# earlgrey register map
Vendor: lowRISC; File version: 0.1
CPU: ibex rev01, little endian, no MPU, no FPU, VTOR, 2 interrupt priority bits, 2 interrupts
Registers are 32-bit, read-write, no defined reset value unless marked. A register's access mark holds for its fields unless they carry their own. Offsets are from the block's base; [hi:lo] are bit positions; {n}, {i} and the like mark numbered series.

## KMAC — Accelerator for Keccak-based keyed hash message authentication code and SHA-3 hash functions; with SCA and FI countermeasures
Base 0x41120000
0x40 CFG_REGWEN ro — Controls the configurability of !!CFG_SHADOWED register.This register ensures the contents of !!CFG_SHADOWED register cannot bechanged by the software while the KMAC/SHA3 is in operation mode.
  [0] en — Configuration enable.
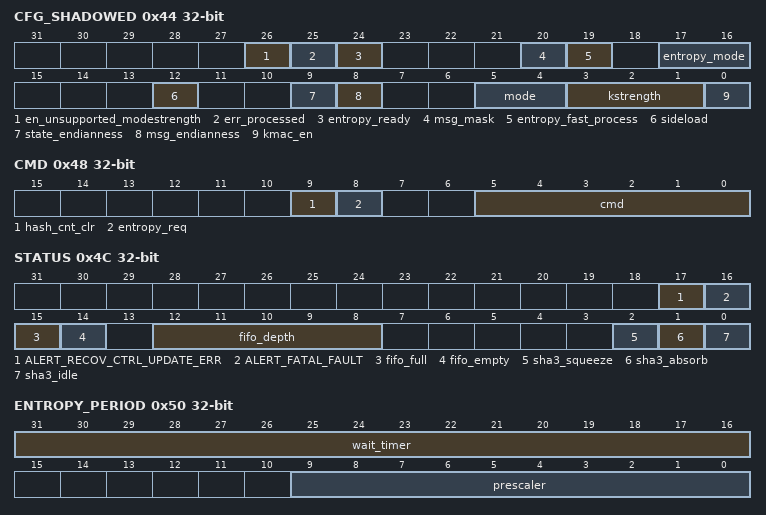
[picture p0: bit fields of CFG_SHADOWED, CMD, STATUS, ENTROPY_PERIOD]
0x44 CFG_SHADOWED — KMAC Configuration register.This register is updated when the hashing engine is in Idle.If the software updates the register while the engine computes, theupdated value will be discarded.
  [26] en_unsupported_modestrength — Enable Unsupported Mode and Strength configs.SW may set this field for KMAC to move forward with unsupportedKeccak Mode and Strength configurations, such as cSHAKE512.If not set, KMAC won't propagate the SW command (CmdStart) to therest of the blocks (AppIntf, KMAC Core, SHA3).
  [25] err_processed — When error occurs and one of the state machine stays at Error handling state, SW may process the error based on ERR_CODE, then let FSM back to the reset state
  [24] entropy_ready — Entropy Ready status.Software sets this field to allow the entropy generator in KMAC tofetch the entropy and run.
  [20] msg_mask — Message Masking with PRNG.If 1, KMAC applies PRNG to the input messages to the Keccak modulewhen KMAC mode is on.
  [19] entropy_fast_process — Entropy Fast process mode.If 1, entropy logic uses garbage data while not processing the KMACkey block. It will re-use previous entropy value and will notexpand the entropy when it is consumed. Only it refreshes theentropy while processing the secret key block. This process shouldnot be used if SCA resistance is required because it may cause sidechannel leakage.
  [17:16] entropy_mode — Entropy ModeUsing this field, software can configure mode of operation of the internal pseudo-random number generator (PRNG).For the hardware to actually switch to an entropy mode other than the default idle_mode, software further needs to set the !!CFG_SHADOWED.entropy_ready bit.After that point, the hardware cannot be made to return to idle_mode unless the module is reset.
  [12] sideload — Sideloaded Key.If 1, KMAC uses KeyMgr sideloaded key for SW initiated KMACoperation. KMAC uses the sideloaded key regardless of thisconfiguration when KeyMgr initiates the KMAC operation forKey Derivation Function (KDF).
  [9] state_endianness — State Endianness.If 1 then each individual word in the !!STATE output registeris converted to big-endian byte order.The order of the words in relation to one another is notchanged.This setting does not affect how the state is interpretedduring computation.
  [8] msg_endianness — Message Endianness.If 1 then each individual multi-byte value, regardless of itsalignment, written to !!MSG_FIFO will be added to the messagein big-endian byte order.If 0, each value will be added to the message in little-endianbyte order.A message written to !!MSG_FIFO one byte at a time will not beaffected by this setting.From a hardware perspective byte swaps are performed on a TL-ULword granularity.
  [5:4] mode — Keccak hashing mode.This module supports SHA3 main hashing algorithm and the partof its derived functions, SHAKE and cSHAKE with limitations.This field is to select the mode.
  [3:1] kstrength — Hashing Strength3 bit field to select the security strength of SHA3 hashingengine. If mode field is set to SHAKE or cSHAKE, only 128 and256 strength can be selected. Other value will result errorwhen hashing starts.
  [0] kmac_en — KMAC datapath enable.If this bit is 1, the incoming message is processed in KMACwith the secret key.
0x48 CMD — KMAC/ SHA3 command register.This register is to control the KMAC to start accepting message,to process the message, and to manually run additional keccakrounds at the end. Only at certain stage, the CMD affects to thecontrol logic. It follows the sequence of`start` --> `process` --> {`run` if needed --> } `done`
  [9] hash_cnt_clr — If writes 1, it clears the hash (KMAC) counter in the entropy module
  [8] entropy_req — SW triggered Entropy RequestIf writes 1 to this field
  [5:0] cmd — Issue a command to the KMAC/SHA3 IP. The command is sparseencoded. To prevent sw from writing multiple commands at once,the field is defined as enum.
0x4C STATUS ro — KMAC/SHA3 Status register.
  [17] ALERT_RECOV_CTRL_UPDATE_ERR — An update error has not occurred (0) or has occured (1) in the shadowed Control Register.KMAC operation needs to be restarted by re-writing the Control Register.
  [16] ALERT_FATAL_FAULT — No fatal fault has occurred inside the KMAC unit (0).A fatal fault has occured and the KMAC unit needs to be reset (1),Examples for such faults includei) TL-UL bus integrity faultii) storage errors in the shadow registersiii) errors in the message, round, or key counteriv) any internal FSM entering an invalid statev) an error in the redundant lfsr
  [15] fifo_full — Message FIFO Full indicator
  [14] fifo_empty — Message FIFO Empty indicator.The FIFO's `Pass` parameter is set to `1'b 1`. So, by default, ifthe SHA engine is ready, the write data to FIFO just passesthrough.In this case, `fifo_depth` remains **0**. `fifo_empty`, however,lowers the value to **0** for a cycle, then goes back to the emptystate, **1**.See the "Message FIFO" section in the spec for the reason.
  [12:8] fifo_depth — Count of occupied entries in the message FIFO.
  [2] sha3_squeeze — If 1, SHA3 completes sponge absorbing stage.In this stage, SW can manually run the hashing engine.
  [1] sha3_absorb — If 1, SHA3 is receiving message stream and processing it
  [0] sha3_idle — If 1, SHA3 hashing engine is in idle state.
0x50 ENTROPY_PERIOD — Entropy Timer Periods.
  [31:16] wait_timer — EDN request wait timer.The entropy module in KMAC waits up to this field in the timer pulseafter it sends request to EDN module. If the timer expires, theentropy module moves to an error state and notifies to the system.If there is a pending EDN request during wait timer update, then this update is delayed until the EDN request is complete.If 0, the entropy module waits the EDN response always. If EDN doesnot respond in this configuration, the software shall reset the IP.
  [9:0] prescaler — EDN Wait timer prescaler.EDN Wait timer has 16 bit value. The timer value is increased when the timer pulse is generated. Timer pulse is raises when the number of the clock cycles hit this prescaler value.The exact period of the timer pulse is unknown as the KMAC input clock may contain jitters.
0x54 ENTROPY_REFRESH_HASH_CNT ro — Entropy Refresh CounterKMAC entropy can be refreshed after the given threshold KMAC operationsrun. If the KMAC hash counter !!ENTROPY_REFRESH_HASH_CNT hits (GTE) theconfigured threshold !!ENTROPY_REFRESH_THRESHOLD_SHADOWED, the entropymodule in the KMAC IP requests new seed to EDN and reset the KMAChash counter.If the threshold is 0, the refresh by the counter does not work. And thecounter is only reset by the CMD.hash_cnt_clr CSR bit.
  [9:0] hash_cnt — Hash (KMAC) counter
0x58 ENTROPY_REFRESH_THRESHOLD_SHADOWED — Entropy Refresh ThresholdKMAC entropy can be refreshed after the given threshold KMAC operationsrun. If the KMAC hash counter !!ENTROPY_REFRESH_HASH_CNT hits (GTE) theconfigured threshold !!ENTROPY_REFRESH_THRESHOLD_SHADOWED, the entropymodule in the KMAC IP requests new seed to EDN and reset the KMAChash counter.If the threshold is 0, the refresh by the counter does not work. And thecounter is only reset by the CMD.hash_cnt_clr CSR bit.
  [9:0] threshold — Hash Threshold
{0x5C+4i} ENTROPY_SEED_{i} wo (i=0..4) — Entropy SeedEntropy seed registers for the integrated entropy generator.If !!CFG_SHADOWED.entropy_mode is set to sw_mode, software first needs to set!!CFG_SHADOWED.entropy_ready and then write the !!ENTROPY_SEED_0 -!!ENTROPY_SEED_4 registers in ascending order. Software writes one 32-bit valueto every register which is subsequently loaded into the corresponding 32-bit LFSRchunk of the entropy generator.After writing all !!ENTROPY_SEED_0 registers, the entropy generator will startits operation. After this point, writing these registers has no longer anyeffect.
  [31:0] seed_{i} — 32-bit chunk of the entropy generator seed
0x70 KEY_SHARE0_0 wo — KMAC Secret KeyKMAC secret key can be up to 512 bit.Order of the secret key is:key[512:0] = {KEY15, KEY14, ... , KEY0};The registers are allowed to be updated when the engine is in Idle state.If the engine computes the hash, it discards any attempts to update the secret keysand report an error.Current KMAC supports up to 512 bit secret key. It is the swresponsibility to keep upper bits of the secret key to 0.
  [31:0] key_0 — 32-bit chunk of up-to 512-bit Secret Key
0x74 KEY_SHARE0_1 wo — KMAC Secret KeyKMAC secret key can be up to 512 bit.Order of the secret key is:key[512:0] = {KEY15, KEY14, ... , KEY0};The registers are allowed to be updated when the engine is in Idle state.If the engine computes the hash, it discards any attempts to update the secret keysand report an error.Current KMAC supports up to 512 bit secret key. It is the swresponsibility to keep upper bits of the secret key to 0.
  [31:0] key_1 — 32-bit chunk of up-to 512-bit Secret Key
0x78 KEY_SHARE0_2 wo — KMAC Secret KeyKMAC secret key can be up to 512 bit.Order of the secret key is:key[512:0] = {KEY15, KEY14, ... , KEY0};The registers are allowed to be updated when the engine is in Idle state.If the engine computes the hash, it discards any attempts to update the secret keysand report an error.Current KMAC supports up to 512 bit secret key. It is the swresponsibility to keep upper bits of the secret key to 0.
  [31:0] key_2 — 32-bit chunk of up-to 512-bit Secret Key
0x7C KEY_SHARE0_3 wo — KMAC Secret KeyKMAC secret key can be up to 512 bit.Order of the secret key is:key[512:0] = {KEY15, KEY14, ... , KEY0};The registers are allowed to be updated when the engine is in Idle state.If the engine computes the hash, it discards any attempts to update the secret keysand report an error.Current KMAC supports up to 512 bit secret key. It is the swresponsibility to keep upper bits of the secret key to 0.
  [31:0] key_3 — 32-bit chunk of up-to 512-bit Secret Key
0x80 KEY_SHARE0_4 wo — KMAC Secret KeyKMAC secret key can be up to 512 bit.Order of the secret key is:key[512:0] = {KEY15, KEY14, ... , KEY0};The registers are allowed to be updated when the engine is in Idle state.If the engine computes the hash, it discards any attempts to update the secret keysand report an error.Current KMAC supports up to 512 bit secret key. It is the swresponsibility to keep upper bits of the secret key to 0.
  [31:0] key_4 — 32-bit chunk of up-to 512-bit Secret Key
0x84 KEY_SHARE0_5 wo — KMAC Secret KeyKMAC secret key can be up to 512 bit.Order of the secret key is:key[512:0] = {KEY15, KEY14, ... , KEY0};The registers are allowed to be updated when the engine is in Idle state.If the engine computes the hash, it discards any attempts to update the secret keysand report an error.Current KMAC supports up to 512 bit secret key. It is the swresponsibility to keep upper bits of the secret key to 0.
  [31:0] key_5 — 32-bit chunk of up-to 512-bit Secret Key
0x88 KEY_SHARE0_6 wo — KMAC Secret KeyKMAC secret key can be up to 512 bit.Order of the secret key is:key[512:0] = {KEY15, KEY14, ... , KEY0};The registers are allowed to be updated when the engine is in Idle state.If the engine computes the hash, it discards any attempts to update the secret keysand report an error.Current KMAC supports up to 512 bit secret key. It is the swresponsibility to keep upper bits of the secret key to 0.
  [31:0] key_6 — 32-bit chunk of up-to 512-bit Secret Key
0x8C KEY_SHARE0_7 wo — KMAC Secret KeyKMAC secret key can be up to 512 bit.Order of the secret key is:key[512:0] = {KEY15, KEY14, ... , KEY0};The registers are allowed to be updated when the engine is in Idle state.If the engine computes the hash, it discards any attempts to update the secret keysand report an error.Current KMAC supports up to 512 bit secret key. It is the swresponsibility to keep upper bits of the secret key to 0.
  [31:0] key_7 — 32-bit chunk of up-to 512-bit Secret Key
0x90 KEY_SHARE0_8 wo — KMAC Secret KeyKMAC secret key can be up to 512 bit.Order of the secret key is:key[512:0] = {KEY15, KEY14, ... , KEY0};The registers are allowed to be updated when the engine is in Idle state.If the engine computes the hash, it discards any attempts to update the secret keysand report an error.Current KMAC supports up to 512 bit secret key. It is the swresponsibility to keep upper bits of the secret key to 0.
  [31:0] key_8 — 32-bit chunk of up-to 512-bit Secret Key
0x94 KEY_SHARE0_9 wo — KMAC Secret KeyKMAC secret key can be up to 512 bit.Order of the secret key is:key[512:0] = {KEY15, KEY14, ... , KEY0};The registers are allowed to be updated when the engine is in Idle state.If the engine computes the hash, it discards any attempts to update the secret keysand report an error.Current KMAC supports up to 512 bit secret key. It is the swresponsibility to keep upper bits of the secret key to 0.
  [31:0] key_9 — 32-bit chunk of up-to 512-bit Secret Key
0x98 KEY_SHARE0_10 wo — KMAC Secret KeyKMAC secret key can be up to 512 bit.Order of the secret key is:key[512:0] = {KEY15, KEY14, ... , KEY0};The registers are allowed to be updated when the engine is in Idle state.If the engine computes the hash, it discards any attempts to update the secret keysand report an error.Current KMAC supports up to 512 bit secret key. It is the swresponsibility to keep upper bits of the secret key to 0.
  [31:0] key_10 — 32-bit chunk of up-to 512-bit Secret Key
0x9C KEY_SHARE0_11 wo — KMAC Secret KeyKMAC secret key can be up to 512 bit.Order of the secret key is:key[512:0] = {KEY15, KEY14, ... , KEY0};The registers are allowed to be updated when the engine is in Idle state.If the engine computes the hash, it discards any attempts to update the secret keysand report an error.Current KMAC supports up to 512 bit secret key. It is the swresponsibility to keep upper bits of the secret key to 0.
  [31:0] key_11 — 32-bit chunk of up-to 512-bit Secret Key
0xA0 KEY_SHARE0_12 wo — KMAC Secret KeyKMAC secret key can be up to 512 bit.Order of the secret key is:key[512:0] = {KEY15, KEY14, ... , KEY0};The registers are allowed to be updated when the engine is in Idle state.If the engine computes the hash, it discards any attempts to update the secret keysand report an error.Current KMAC supports up to 512 bit secret key. It is the swresponsibility to keep upper bits of the secret key to 0.
  [31:0] key_12 — 32-bit chunk of up-to 512-bit Secret Key
0xA4 KEY_SHARE0_13 wo — KMAC Secret KeyKMAC secret key can be up to 512 bit.Order of the secret key is:key[512:0] = {KEY15, KEY14, ... , KEY0};The registers are allowed to be updated when the engine is in Idle state.If the engine computes the hash, it discards any attempts to update the secret keysand report an error.Current KMAC supports up to 512 bit secret key. It is the swresponsibility to keep upper bits of the secret key to 0.
  [31:0] key_13 — 32-bit chunk of up-to 512-bit Secret Key
0xA8 KEY_SHARE0_14 wo — KMAC Secret KeyKMAC secret key can be up to 512 bit.Order of the secret key is:key[512:0] = {KEY15, KEY14, ... , KEY0};The registers are allowed to be updated when the engine is in Idle state.If the engine computes the hash, it discards any attempts to update the secret keysand report an error.Current KMAC supports up to 512 bit secret key. It is the swresponsibility to keep upper bits of the secret key to 0.
  [31:0] key_14 — 32-bit chunk of up-to 512-bit Secret Key
0xAC KEY_SHARE0_15 wo — KMAC Secret KeyKMAC secret key can be up to 512 bit.Order of the secret key is:key[512:0] = {KEY15, KEY14, ... , KEY0};The registers are allowed to be updated when the engine is in Idle state.If the engine computes the hash, it discards any attempts to update the secret keysand report an error.Current KMAC supports up to 512 bit secret key. It is the swresponsibility to keep upper bits of the secret key to 0.
  [31:0] key_15 — 32-bit chunk of up-to 512-bit Secret Key
0xB0 KEY_SHARE1_0 wo — KMAC Secret Key, 2nd share.KMAC secret key can be up to 512 bit.Order of the secret key is:key[512:0] = {KEY15, KEY14, ... , KEY0};The registers are allowed to be updated when the engine is in Idle state.If the engine computes the hash, it discards any attempts to update the secret keysand report an error.Current KMAC supports up to 512 bit secret key. It is the swresponsibility to keep upper bits of the secret key to 0.
  [31:0] key_0 — 32-bit chunk of up-to 512-bit Secret Key
0xB4 KEY_SHARE1_1 wo — KMAC Secret Key, 2nd share.KMAC secret key can be up to 512 bit.Order of the secret key is:key[512:0] = {KEY15, KEY14, ... , KEY0};The registers are allowed to be updated when the engine is in Idle state.If the engine computes the hash, it discards any attempts to update the secret keysand report an error.Current KMAC supports up to 512 bit secret key. It is the swresponsibility to keep upper bits of the secret key to 0.
  [31:0] key_1 — 32-bit chunk of up-to 512-bit Secret Key
0xB8 KEY_SHARE1_2 wo — KMAC Secret Key, 2nd share.KMAC secret key can be up to 512 bit.Order of the secret key is:key[512:0] = {KEY15, KEY14, ... , KEY0};The registers are allowed to be updated when the engine is in Idle state.If the engine computes the hash, it discards any attempts to update the secret keysand report an error.Current KMAC supports up to 512 bit secret key. It is the swresponsibility to keep upper bits of the secret key to 0.
  [31:0] key_2 — 32-bit chunk of up-to 512-bit Secret Key
0xBC KEY_SHARE1_3 wo — KMAC Secret Key, 2nd share.KMAC secret key can be up to 512 bit.Order of the secret key is:key[512:0] = {KEY15, KEY14, ... , KEY0};The registers are allowed to be updated when the engine is in Idle state.If the engine computes the hash, it discards any attempts to update the secret keysand report an error.Current KMAC supports up to 512 bit secret key. It is the swresponsibility to keep upper bits of the secret key to 0.
  [31:0] key_3 — 32-bit chunk of up-to 512-bit Secret Key
0xC0 KEY_SHARE1_4 wo — KMAC Secret Key, 2nd share.KMAC secret key can be up to 512 bit.Order of the secret key is:key[512:0] = {KEY15, KEY14, ... , KEY0};The registers are allowed to be updated when the engine is in Idle state.If the engine computes the hash, it discards any attempts to update the secret keysand report an error.Current KMAC supports up to 512 bit secret key. It is the swresponsibility to keep upper bits of the secret key to 0.
  [31:0] key_4 — 32-bit chunk of up-to 512-bit Secret Key
0xC4 KEY_SHARE1_5 wo — KMAC Secret Key, 2nd share.KMAC secret key can be up to 512 bit.Order of the secret key is:key[512:0] = {KEY15, KEY14, ... , KEY0};The registers are allowed to be updated when the engine is in Idle state.If the engine computes the hash, it discards any attempts to update the secret keysand report an error.Current KMAC supports up to 512 bit secret key. It is the swresponsibility to keep upper bits of the secret key to 0.
  [31:0] key_5 — 32-bit chunk of up-to 512-bit Secret Key
0xC8 KEY_SHARE1_6 wo — KMAC Secret Key, 2nd share.KMAC secret key can be up to 512 bit.Order of the secret key is:key[512:0] = {KEY15, KEY14, ... , KEY0};The registers are allowed to be updated when the engine is in Idle state.If the engine computes the hash, it discards any attempts to update the secret keysand report an error.Current KMAC supports up to 512 bit secret key. It is the swresponsibility to keep upper bits of the secret key to 0.
  [31:0] key_6 — 32-bit chunk of up-to 512-bit Secret Key
0xCC KEY_SHARE1_7 wo — KMAC Secret Key, 2nd share.KMAC secret key can be up to 512 bit.Order of the secret key is:key[512:0] = {KEY15, KEY14, ... , KEY0};The registers are allowed to be updated when the engine is in Idle state.If the engine computes the hash, it discards any attempts to update the secret keysand report an error.Current KMAC supports up to 512 bit secret key. It is the swresponsibility to keep upper bits of the secret key to 0.
  [31:0] key_7 — 32-bit chunk of up-to 512-bit Secret Key
0xD0 KEY_SHARE1_8 wo — KMAC Secret Key, 2nd share.KMAC secret key can be up to 512 bit.Order of the secret key is:key[512:0] = {KEY15, KEY14, ... , KEY0};The registers are allowed to be updated when the engine is in Idle state.If the engine computes the hash, it discards any attempts to update the secret keysand report an error.Current KMAC supports up to 512 bit secret key. It is the swresponsibility to keep upper bits of the secret key to 0.
  [31:0] key_8 — 32-bit chunk of up-to 512-bit Secret Key
0xD4 KEY_SHARE1_9 wo — KMAC Secret Key, 2nd share.KMAC secret key can be up to 512 bit.Order of the secret key is:key[512:0] = {KEY15, KEY14, ... , KEY0};The registers are allowed to be updated when the engine is in Idle state.If the engine computes the hash, it discards any attempts to update the secret keysand report an error.Current KMAC supports up to 512 bit secret key. It is the swresponsibility to keep upper bits of the secret key to 0.
  [31:0] key_9 — 32-bit chunk of up-to 512-bit Secret Key
0xD8 KEY_SHARE1_10 wo — KMAC Secret Key, 2nd share.KMAC secret key can be up to 512 bit.Order of the secret key is:key[512:0] = {KEY15, KEY14, ... , KEY0};The registers are allowed to be updated when the engine is in Idle state.If the engine computes the hash, it discards any attempts to update the secret keysand report an error.Current KMAC supports up to 512 bit secret key. It is the swresponsibility to keep upper bits of the secret key to 0.
  [31:0] key_10 — 32-bit chunk of up-to 512-bit Secret Key
0xDC KEY_SHARE1_11 wo — KMAC Secret Key, 2nd share.KMAC secret key can be up to 512 bit.Order of the secret key is:key[512:0] = {KEY15, KEY14, ... , KEY0};The registers are allowed to be updated when the engine is in Idle state.If the engine computes the hash, it discards any attempts to update the secret keysand report an error.Current KMAC supports up to 512 bit secret key. It is the swresponsibility to keep upper bits of the secret key to 0.
  [31:0] key_11 — 32-bit chunk of up-to 512-bit Secret Key
0xE0 KEY_SHARE1_12 wo — KMAC Secret Key, 2nd share.KMAC secret key can be up to 512 bit.Order of the secret key is:key[512:0] = {KEY15, KEY14, ... , KEY0};The registers are allowed to be updated when the engine is in Idle state.If the engine computes the hash, it discards any attempts to update the secret keysand report an error.Current KMAC supports up to 512 bit secret key. It is the swresponsibility to keep upper bits of the secret key to 0.
  [31:0] key_12 — 32-bit chunk of up-to 512-bit Secret Key
0xE4 KEY_SHARE1_13 wo — KMAC Secret Key, 2nd share.KMAC secret key can be up to 512 bit.Order of the secret key is:key[512:0] = {KEY15, KEY14, ... , KEY0};The registers are allowed to be updated when the engine is in Idle state.If the engine computes the hash, it discards any attempts to update the secret keysand report an error.Current KMAC supports up to 512 bit secret key. It is the swresponsibility to keep upper bits of the secret key to 0.
  [31:0] key_13 — 32-bit chunk of up-to 512-bit Secret Key
0xE8 KEY_SHARE1_14 wo — KMAC Secret Key, 2nd share.KMAC secret key can be up to 512 bit.Order of the secret key is:key[512:0] = {KEY15, KEY14, ... , KEY0};The registers are allowed to be updated when the engine is in Idle state.If the engine computes the hash, it discards any attempts to update the secret keysand report an error.Current KMAC supports up to 512 bit secret key. It is the swresponsibility to keep upper bits of the secret key to 0.
  [31:0] key_14 — 32-bit chunk of up-to 512-bit Secret Key
0xEC KEY_SHARE1_15 wo — KMAC Secret Key, 2nd share.KMAC secret key can be up to 512 bit.Order of the secret key is:key[512:0] = {KEY15, KEY14, ... , KEY0};The registers are allowed to be updated when the engine is in Idle state.If the engine computes the hash, it discards any attempts to update the secret keysand report an error.Current KMAC supports up to 512 bit secret key. It is the swresponsibility to keep upper bits of the secret key to 0.
  [31:0] key_15 — 32-bit chunk of up-to 512-bit Secret Key
0xF0 KEY_LEN wo — Secret Key length in bit.This value is used to make encoded secret key in KMAC.KMAC supports certain lengths of the secret key. Currently itsupports 128b, 192b, 256b, 384b, and 512b secret keys.
  [2:0] len — Key length choice
0xF4 PREFIX_0 — cSHAKE Prefix register.Prefix including Function Name N and Customization String S.The SHA3 assumes this register value is encoded as:`encode_string(N) || encode_string(S) || 0`. It means that thesoftware can freely decide the length of N or S based on thegiven Prefix register size 320bit. 320bit is determined to have32-bit of N and up to 256-bit of S + encode of their length.It is SW responsibility to fill the register with encoded valuethat is described at Section 2.3.2 String Encoding in NIST SP800-185 specification.Order of Prefix is:prefix[end:0] := {PREFIX(N-1), ..., PREFIX(1), PREFIX(0) }The registers are allowed to be updated when the engine is in Idle state.If the engine computes the hash, it discards any attempts to update the secret keysand report an error.
  [31:0] prefix_0 — 32-bit chunk of Encoded NS Prefix
0xF8 PREFIX_1 — cSHAKE Prefix register.Prefix including Function Name N and Customization String S.The SHA3 assumes this register value is encoded as:`encode_string(N) || encode_string(S) || 0`. It means that thesoftware can freely decide the length of N or S based on thegiven Prefix register size 320bit. 320bit is determined to have32-bit of N and up to 256-bit of S + encode of their length.It is SW responsibility to fill the register with encoded valuethat is described at Section 2.3.2 String Encoding in NIST SP800-185 specification.Order of Prefix is:prefix[end:0] := {PREFIX(N-1), ..., PREFIX(1), PREFIX(0) }The registers are allowed to be updated when the engine is in Idle state.If the engine computes the hash, it discards any attempts to update the secret keysand report an error.
  [31:0] prefix_1 — 32-bit chunk of Encoded NS Prefix
0xFC PREFIX_2 — cSHAKE Prefix register.Prefix including Function Name N and Customization String S.The SHA3 assumes this register value is encoded as:`encode_string(N) || encode_string(S) || 0`. It means that thesoftware can freely decide the length of N or S based on thegiven Prefix register size 320bit. 320bit is determined to have32-bit of N and up to 256-bit of S + encode of their length.It is SW responsibility to fill the register with encoded valuethat is described at Section 2.3.2 String Encoding in NIST SP800-185 specification.Order of Prefix is:prefix[end:0] := {PREFIX(N-1), ..., PREFIX(1), PREFIX(0) }The registers are allowed to be updated when the engine is in Idle state.If the engine computes the hash, it discards any attempts to update the secret keysand report an error.
  [31:0] prefix_2 — 32-bit chunk of Encoded NS Prefix
0x100 PREFIX_3 — cSHAKE Prefix register.Prefix including Function Name N and Customization String S.The SHA3 assumes this register value is encoded as:`encode_string(N) || encode_string(S) || 0`. It means that thesoftware can freely decide the length of N or S based on thegiven Prefix register size 320bit. 320bit is determined to have32-bit of N and up to 256-bit of S + encode of their length.It is SW responsibility to fill the register with encoded valuethat is described at Section 2.3.2 String Encoding in NIST SP800-185 specification.Order of Prefix is:prefix[end:0] := {PREFIX(N-1), ..., PREFIX(1), PREFIX(0) }The registers are allowed to be updated when the engine is in Idle state.If the engine computes the hash, it discards any attempts to update the secret keysand report an error.
  [31:0] prefix_3 — 32-bit chunk of Encoded NS Prefix
0x104 PREFIX_4 — cSHAKE Prefix register.Prefix including Function Name N and Customization String S.The SHA3 assumes this register value is encoded as:`encode_string(N) || encode_string(S) || 0`. It means that thesoftware can freely decide the length of N or S based on thegiven Prefix register size 320bit. 320bit is determined to have32-bit of N and up to 256-bit of S + encode of their length.It is SW responsibility to fill the register with encoded valuethat is described at Section 2.3.2 String Encoding in NIST SP800-185 specification.Order of Prefix is:prefix[end:0] := {PREFIX(N-1), ..., PREFIX(1), PREFIX(0) }The registers are allowed to be updated when the engine is in Idle state.If the engine computes the hash, it discards any attempts to update the secret keysand report an error.
  [31:0] prefix_4 — 32-bit chunk of Encoded NS Prefix
0x108 PREFIX_5 — cSHAKE Prefix register.Prefix including Function Name N and Customization String S.The SHA3 assumes this register value is encoded as:`encode_string(N) || encode_string(S) || 0`. It means that thesoftware can freely decide the length of N or S based on thegiven Prefix register size 320bit. 320bit is determined to have32-bit of N and up to 256-bit of S + encode of their length.It is SW responsibility to fill the register with encoded valuethat is described at Section 2.3.2 String Encoding in NIST SP800-185 specification.Order of Prefix is:prefix[end:0] := {PREFIX(N-1), ..., PREFIX(1), PREFIX(0) }The registers are allowed to be updated when the engine is in Idle state.If the engine computes the hash, it discards any attempts to update the secret keysand report an error.
  [31:0] prefix_5 — 32-bit chunk of Encoded NS Prefix
0x10C PREFIX_6 — cSHAKE Prefix register.Prefix including Function Name N and Customization String S.The SHA3 assumes this register value is encoded as:`encode_string(N) || encode_string(S) || 0`. It means that thesoftware can freely decide the length of N or S based on thegiven Prefix register size 320bit. 320bit is determined to have32-bit of N and up to 256-bit of S + encode of their length.It is SW responsibility to fill the register with encoded valuethat is described at Section 2.3.2 String Encoding in NIST SP800-185 specification.Order of Prefix is:prefix[end:0] := {PREFIX(N-1), ..., PREFIX(1), PREFIX(0) }The registers are allowed to be updated when the engine is in Idle state.If the engine computes the hash, it discards any attempts to update the secret keysand report an error.
  [31:0] prefix_6 — 32-bit chunk of Encoded NS Prefix
0x110 PREFIX_7 — cSHAKE Prefix register.Prefix including Function Name N and Customization String S.The SHA3 assumes this register value is encoded as:`encode_string(N) || encode_string(S) || 0`. It means that thesoftware can freely decide the length of N or S based on thegiven Prefix register size 320bit. 320bit is determined to have32-bit of N and up to 256-bit of S + encode of their length.It is SW responsibility to fill the register with encoded valuethat is described at Section 2.3.2 String Encoding in NIST SP800-185 specification.Order of Prefix is:prefix[end:0] := {PREFIX(N-1), ..., PREFIX(1), PREFIX(0) }The registers are allowed to be updated when the engine is in Idle state.If the engine computes the hash, it discards any attempts to update the secret keysand report an error.
  [31:0] prefix_7 — 32-bit chunk of Encoded NS Prefix
0x114 PREFIX_8 — cSHAKE Prefix register.Prefix including Function Name N and Customization String S.The SHA3 assumes this register value is encoded as:`encode_string(N) || encode_string(S) || 0`. It means that thesoftware can freely decide the length of N or S based on thegiven Prefix register size 320bit. 320bit is determined to have32-bit of N and up to 256-bit of S + encode of their length.It is SW responsibility to fill the register with encoded valuethat is described at Section 2.3.2 String Encoding in NIST SP800-185 specification.Order of Prefix is:prefix[end:0] := {PREFIX(N-1), ..., PREFIX(1), PREFIX(0) }The registers are allowed to be updated when the engine is in Idle state.If the engine computes the hash, it discards any attempts to update the secret keysand report an error.
  [31:0] prefix_8 — 32-bit chunk of Encoded NS Prefix
0x118 PREFIX_9 — cSHAKE Prefix register.Prefix including Function Name N and Customization String S.The SHA3 assumes this register value is encoded as:`encode_string(N) || encode_string(S) || 0`. It means that thesoftware can freely decide the length of N or S based on thegiven Prefix register size 320bit. 320bit is determined to have32-bit of N and up to 256-bit of S + encode of their length.It is SW responsibility to fill the register with encoded valuethat is described at Section 2.3.2 String Encoding in NIST SP800-185 specification.Order of Prefix is:prefix[end:0] := {PREFIX(N-1), ..., PREFIX(1), PREFIX(0) }The registers are allowed to be updated when the engine is in Idle state.If the engine computes the hash, it discards any attempts to update the secret keysand report an error.
  [31:0] prefix_9 — 32-bit chunk of Encoded NS Prefix
0x11C PREFIX_10 — cSHAKE Prefix register.Prefix including Function Name N and Customization String S.The SHA3 assumes this register value is encoded as:`encode_string(N) || encode_string(S) || 0`. It means that thesoftware can freely decide the length of N or S based on thegiven Prefix register size 320bit. 320bit is determined to have32-bit of N and up to 256-bit of S + encode of their length.It is SW responsibility to fill the register with encoded valuethat is described at Section 2.3.2 String Encoding in NIST SP800-185 specification.Order of Prefix is:prefix[end:0] := {PREFIX(N-1), ..., PREFIX(1), PREFIX(0) }The registers are allowed to be updated when the engine is in Idle state.If the engine computes the hash, it discards any attempts to update the secret keysand report an error.
  [31:0] prefix_10 — 32-bit chunk of Encoded NS Prefix
0x120 ERR_CODE ro — KMAC/SHA3 Error Code
  [31:0] err_code — If error interrupt occurs, this register has information of error cause.Please take a look at `hw/ip/kmac/rtl/kmac_pkg.sv:err_code_e enum type.
